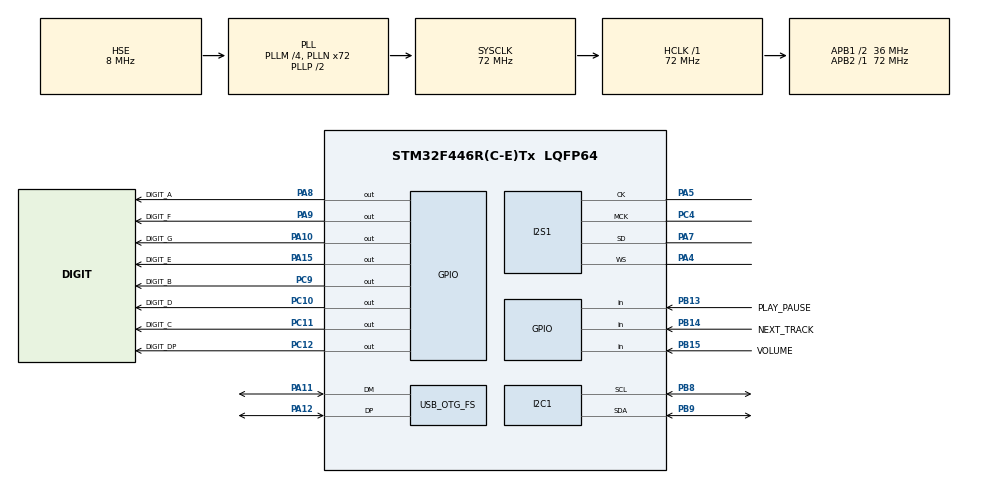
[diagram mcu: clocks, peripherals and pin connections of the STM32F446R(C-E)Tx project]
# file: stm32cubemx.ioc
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Dma.Request0=SPI1_TX
Dma.SPI1_TX.0.Direction=DMA_MEMORY_TO_PERIPH
Dma.SPI1_TX.0.FIFOMode=DMA_FIFOMODE_DISABLE
Dma.SPI1_TX.0.Instance=DMA2_Stream3
Dma.SPI1_TX.0.MemDataAlignment=DMA_MDATAALIGN_HALFWORD
Dma.SPI1_TX.0.MemInc=DMA_MINC_ENABLE
Dma.SPI1_TX.0.Mode=DMA_CIRCULAR
Dma.SPI1_TX.0.PeriphDataAlignment=DMA_PDATAALIGN_HALFWORD
Dma.SPI1_TX.0.PeriphInc=DMA_PINC_DISABLE
Dma.SPI1_TX.0.Priority=DMA_PRIORITY_LOW
FATFS._CODE_PAGE=932
I2S1.AudioFreq=I2S_AUDIOFREQ_44K
I2S1.ErrorAudioFreq=0.24 %
I2S1.FullDuplexMode=I2S_FULLDUPLEXMODE_DISABLE
I2S1.Instance=SPI$Index
I2S1.RealAudioFreq=44.108 KHz
I2S1.VirtualMode=I2S_MODE_MASTER
Mcu.Family=STM32F4
Mcu.Name=STM32F446R(C-E)Tx
Mcu.Package=LQFP64
NVIC.DMA2_Stream3_IRQn=true\:0\:0\:false\:false\:true\:false\:true\:true
NVIC.OTG_FS_IRQn=true\:0\:0\:false\:false\:true\:false\:true\:true
NVIC.PriorityGroup=NVIC_PRIORITYGROUP_4
NVIC.SPI1_IRQn=true\:0\:0\:false\:false\:true\:true\:true\:true
PA10.GPIO_Label=DIGIT_G
PA10.Signal=GPIO_Output
PA11.Mode=Host_Only
PA11.Signal=USB_OTG_FS_DM
PA12.Mode=Host_Only
PA12.Signal=USB_OTG_FS_DP
PA13.Mode=Serial_Wire
PA13.Signal=SYS_JTMS-SWDIO
PA14.Mode=Serial_Wire
PA14.Signal=SYS_JTCK-SWCLK
PA15.GPIO_Label=DIGIT_E
PA15.Signal=GPIO_Output
PA4.Mode=Half_Duplex_Master
PA4.Signal=I2S1_WS
PA5.Mode=Half_Duplex_Master
PA5.Signal=I2S1_CK
PA7.Mode=Half_Duplex_Master
PA7.Signal=I2S1_SD
PA8.GPIO_Label=DIGIT_A
PA8.Signal=GPIO_Output
PA9.GPIO_Label=DIGIT_F
PA9.Signal=GPIO_Output
PB13.GPIO_Label=PLAY_PAUSE
PB13.GPIO_PuPd=GPIO_PULLUP
PB13.Signal=GPIO_Input
PB14.GPIO_Label=NEXT_TRACK
PB14.GPIO_PuPd=GPIO_PULLUP
PB14.Signal=GPIO_Input
PB15.GPIO_Label=VOLUME
PB15.GPIO_PuPd=GPIO_PULLUP
PB15.Signal=GPIO_Input
PB8.Mode=I2C
PB8.Signal=I2C1_SCL
PB9.Mode=I2C
PB9.Signal=I2C1_SDA
PC10.GPIO_Label=DIGIT_D
PC10.Signal=GPIO_Output
PC11.GPIO_Label=DIGIT_C
PC11.Signal=GPIO_Output
PC12.GPIO_Label=DIGIT_DP
PC12.Signal=GPIO_Output
PC4.Mode=Master_Clock_Activated
PC4.Signal=I2S1_MCK
PC9.GPIO_Label=DIGIT_B
PC9.Signal=GPIO_Output
PH0-OSC_IN.Mode=HSE-External-Oscillator
PH0-OSC_IN.Signal=RCC_OSC_IN
PH1-OSC_OUT.Mode=HSE-External-Oscillator
PH1-OSC_OUT.Signal=RCC_OSC_OUT
ProjectManager.HeapSize=0x200
ProjectManager.StackSize=0x400
ProjectManager.TargetToolchain=Makefile
RCC.AHBFreq_Value=72000000
RCC.APB1CLKDivider=RCC_HCLK_DIV2
RCC.APB1Freq_Value=36000000
RCC.APB1TimFreq_Value=72000000
RCC.APB2Freq_Value=72000000
RCC.APB2TimFreq_Value=72000000
RCC.CortexFreq_Value=72000000
RCC.HCLKFreq_Value=72000000
RCC.HSE_VALUE=8000000
RCC.PLLI2SM=8
RCC.PLLI2SN=271
RCC.PLLI2SR=6
RCC.PLLM=4
RCC.PLLN=72
RCC.PLLQ=3
RCC.PLLSourceVirtual=RCC_PLLSOURCE_HSE
RCC.SYSCLKFreq_VALUE=72000000
RCC.SYSCLKSource=RCC_SYSCLKSOURCE_PLLCLK
RCC.USBFreq_Value=48000000
RCC.VCOOutputFreq_Value=144000000
USB_HOST.USBH_HandleTypeDef-MSC_FS=hUsbHostFS
USB_HOST.VirtualModeFS=Msc
USB_OTG_FS.VirtualMode=Host_Only
USB_OTG_FS.phy_itface=HCD_PHY_EMBEDDED
VP_FATFS_VS_USB.Mode=USB
VP_USB_HOST_VS_USB_HOST_MSC_FS.Mode=MSC_FS
board=custom

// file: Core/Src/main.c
/* USER CODE BEGIN Header */
/**
  ******************************************************************************
  * @file           : main.c
  * @brief          : Main program body
  ******************************************************************************
  * @attention
  *
  * Copyright (c) 2026 STMicroelectronics.
  * All rights reserved.
  *
  * This software is licensed under terms that can be found in the LICENSE file
  * in the root directory of this software component.
  * If no LICENSE file comes with this software, it is provided AS-IS.
  *
  ******************************************************************************
  */
/* USER CODE END Header */
#include "main.h"
#include "fatfs.h"
#include "usb_host.h"

I2C_HandleTypeDef hi2c1;

I2S_HandleTypeDef hi2s1;
DMA_HandleTypeDef hdma_spi1_tx;

void SystemClock_Config(void);
static void MX_GPIO_Init(void);
static void MX_DMA_Init(void);
static void MX_I2C1_Init(void);
static void MX_I2S1_Init(void);
void MX_USB_HOST_Process(void);

/* USER CODE BEGIN PFP */
void entry_c(void);
/* USER CODE END PFP */

int main(void)
{

  /* MCU Configuration--------------------------------------------------------*/

  /* Reset of all peripherals, Initializes the Flash interface and the Systick. */
  HAL_Init();

  /* Configure the system clock */
  SystemClock_Config();

  /* Initialize all configured peripherals */
  MX_GPIO_Init();
  MX_DMA_Init();
  MX_I2C1_Init();
  MX_I2S1_Init();
  MX_USB_HOST_Init();
  MX_FATFS_Init();
  /* USER CODE BEGIN 2 */
  entry_c();
  /* USER CODE END 2 */

  /* Infinite loop */
  while (1)
  {
    MX_USB_HOST_Process();

  }
}

void SystemClock_Config(void)
{
  RCC_OscInitTypeDef RCC_OscInitStruct = {0};
  RCC_ClkInitTypeDef RCC_ClkInitStruct = {0};

  /** Configure the main internal regulator output voltage
  */
  __HAL_RCC_PWR_CLK_ENABLE();
  __HAL_PWR_VOLTAGESCALING_CONFIG(PWR_REGULATOR_VOLTAGE_SCALE3);

  /** Initializes the RCC Oscillators according to the specified parameters
  * in the RCC_OscInitTypeDef structure.
  */
  RCC_OscInitStruct.OscillatorType = RCC_OSCILLATORTYPE_HSE;
  RCC_OscInitStruct.HSEState = RCC_HSE_ON;
  RCC_OscInitStruct.PLL.PLLState = RCC_PLL_ON;
  RCC_OscInitStruct.PLL.PLLSource = RCC_PLLSOURCE_HSE;
  RCC_OscInitStruct.PLL.PLLM = 4;
  RCC_OscInitStruct.PLL.PLLN = 72;
  RCC_OscInitStruct.PLL.PLLP = RCC_PLLP_DIV2;
  RCC_OscInitStruct.PLL.PLLQ = 3;
  RCC_OscInitStruct.PLL.PLLR = 2;
  if (HAL_RCC_OscConfig(&RCC_OscInitStruct) != HAL_OK)
  {
    Error_Handler();
  }

  /** Initializes the CPU, AHB and APB buses clocks
  */
  RCC_ClkInitStruct.ClockType = RCC_CLOCKTYPE_HCLK|RCC_CLOCKTYPE_SYSCLK
                              |RCC_CLOCKTYPE_PCLK1|RCC_CLOCKTYPE_PCLK2;
  RCC_ClkInitStruct.SYSCLKSource = RCC_SYSCLKSOURCE_PLLCLK;
  RCC_ClkInitStruct.AHBCLKDivider = RCC_SYSCLK_DIV1;
  RCC_ClkInitStruct.APB1CLKDivider = RCC_HCLK_DIV2;
  RCC_ClkInitStruct.APB2CLKDivider = RCC_HCLK_DIV1;

  if (HAL_RCC_ClockConfig(&RCC_ClkInitStruct, FLASH_LATENCY_2) != HAL_OK)
  {
    Error_Handler();
  }
}

static void MX_I2C1_Init(void)
{

  hi2c1.Instance = I2C1;
  hi2c1.Init.ClockSpeed = 100000;
  hi2c1.Init.DutyCycle = I2C_DUTYCYCLE_2;
  hi2c1.Init.OwnAddress1 = 0;
  hi2c1.Init.AddressingMode = I2C_ADDRESSINGMODE_7BIT;
  hi2c1.Init.DualAddressMode = I2C_DUALADDRESS_DISABLE;
  hi2c1.Init.OwnAddress2 = 0;
  hi2c1.Init.GeneralCallMode = I2C_GENERALCALL_DISABLE;
  hi2c1.Init.NoStretchMode = I2C_NOSTRETCH_DISABLE;
  if (HAL_I2C_Init(&hi2c1) != HAL_OK)
  {
    Error_Handler();
  }

}

static void MX_I2S1_Init(void)
{

  hi2s1.Instance = SPI1;
  hi2s1.Init.Mode = I2S_MODE_MASTER_TX;
  hi2s1.Init.Standard = I2S_STANDARD_PHILIPS;
  hi2s1.Init.DataFormat = I2S_DATAFORMAT_16B;
  hi2s1.Init.MCLKOutput = I2S_MCLKOUTPUT_ENABLE;
  hi2s1.Init.AudioFreq = I2S_AUDIOFREQ_44K;
  hi2s1.Init.CPOL = I2S_CPOL_LOW;
  hi2s1.Init.ClockSource = I2S_CLOCK_PLL;
  hi2s1.Init.FullDuplexMode = I2S_FULLDUPLEXMODE_DISABLE;
  if (HAL_I2S_Init(&hi2s1) != HAL_OK)
  {
    Error_Handler();
  }

}

static void MX_DMA_Init(void)
{

  /* DMA controller clock enable */
  __HAL_RCC_DMA2_CLK_ENABLE();

  /* DMA interrupt init */
  /* DMA2_Stream3_IRQn interrupt configuration */
  HAL_NVIC_SetPriority(DMA2_Stream3_IRQn, 0, 0);
  HAL_NVIC_EnableIRQ(DMA2_Stream3_IRQn);

}

static void MX_GPIO_Init(void)
{
  GPIO_InitTypeDef GPIO_InitStruct = {0};

  /* GPIO Ports Clock Enable */
  __HAL_RCC_GPIOH_CLK_ENABLE();
  __HAL_RCC_GPIOA_CLK_ENABLE();
  __HAL_RCC_GPIOC_CLK_ENABLE();
  __HAL_RCC_GPIOB_CLK_ENABLE();

  /*Configure GPIO pin Output Level */
  HAL_GPIO_WritePin(GPIOC, DIGIT_B_Pin|DIGIT_D_Pin|DIGIT_C_Pin|DIGIT_DP_Pin, GPIO_PIN_RESET);

  /*Configure GPIO pin Output Level */
  HAL_GPIO_WritePin(GPIOA, DIGIT_A_Pin|DIGIT_F_Pin|DIGIT_G_Pin|DIGIT_E_Pin, GPIO_PIN_RESET);

  /*Configure GPIO pins : PLAY_PAUSE_Pin NEXT_TRACK_Pin VOLUME_Pin */
  GPIO_InitStruct.Pin = PLAY_PAUSE_Pin|NEXT_TRACK_Pin|VOLUME_Pin;
  GPIO_InitStruct.Mode = GPIO_MODE_INPUT;
  GPIO_InitStruct.Pull = GPIO_PULLUP;
  HAL_GPIO_Init(GPIOB, &GPIO_InitStruct);

  /*Configure GPIO pins : DIGIT_B_Pin DIGIT_D_Pin DIGIT_C_Pin DIGIT_DP_Pin */
  GPIO_InitStruct.Pin = DIGIT_B_Pin|DIGIT_D_Pin|DIGIT_C_Pin|DIGIT_DP_Pin;
  GPIO_InitStruct.Mode = GPIO_MODE_OUTPUT_PP;
  GPIO_InitStruct.Pull = GPIO_NOPULL;
  GPIO_InitStruct.Speed = GPIO_SPEED_FREQ_LOW;
  HAL_GPIO_Init(GPIOC, &GPIO_InitStruct);

  /*Configure GPIO pins : DIGIT_A_Pin DIGIT_F_Pin DIGIT_G_Pin DIGIT_E_Pin */
  GPIO_InitStruct.Pin = DIGIT_A_Pin|DIGIT_F_Pin|DIGIT_G_Pin|DIGIT_E_Pin;
  GPIO_InitStruct.Mode = GPIO_MODE_OUTPUT_PP;
  GPIO_InitStruct.Pull = GPIO_NOPULL;
  GPIO_InitStruct.Speed = GPIO_SPEED_FREQ_LOW;
  HAL_GPIO_Init(GPIOA, &GPIO_InitStruct);

}

void Error_Handler(void)
{
  __disable_irq();
  while (1)
  {
  }
}
